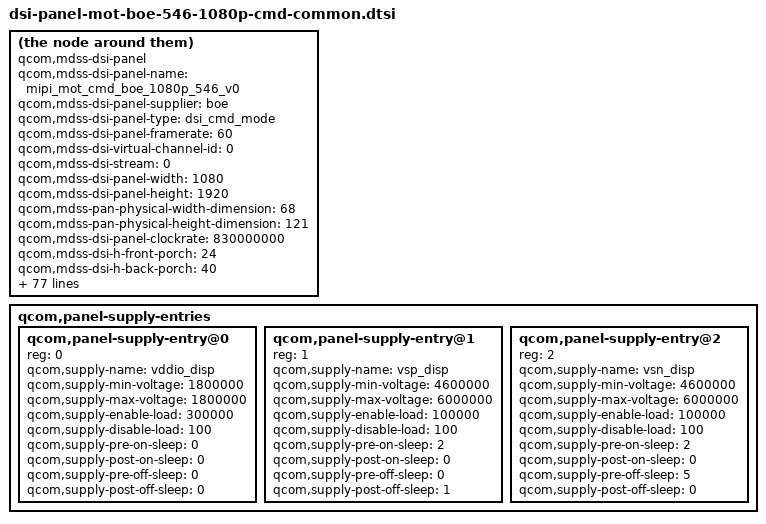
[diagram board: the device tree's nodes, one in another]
/* Copyright (c) 2015, The Linux Foundation. All rights reserved.
 *
 * This program is free software; you can redistribute it and/or modify
 * it under the terms of the GNU General Public License version 2 and
 * only version 2 as published by the Free Software Foundation.
 *
 * This program is distributed in the hope that it will be useful,
 * but WITHOUT ANY WARRANTY; without even the implied warranty of
 * MERCHANTABILITY or FITNESS FOR A PARTICULAR PURPOSE.  See the
 * GNU General Public License for more details.
 */

compatible = "qcom,mdss-dsi-panel";
qcom,mdss-dsi-panel-name = "mipi_mot_cmd_boe_1080p_546_v0";
qcom,mdss-dsi-panel-supplier = "boe";
qcom,mdss-dsi-panel-type = "dsi_cmd_mode";
qcom,mdss-dsi-panel-framerate = <60>;
qcom,mdss-dsi-virtual-channel-id = <0>;
qcom,mdss-dsi-stream = <0>;
qcom,mdss-dsi-panel-width = <1080>;
qcom,mdss-dsi-panel-height = <1920>;
/* Todo: update dimension values based on BOE spec. */
qcom,mdss-pan-physical-width-dimension = <68>;
qcom,mdss-pan-physical-height-dimension = <121>;

qcom,mdss-dsi-panel-clockrate = <830000000>;
qcom,mdss-dsi-h-front-porch = <24>;
qcom,mdss-dsi-h-back-porch = <40>;
qcom,mdss-dsi-h-pulse-width = <4>;
qcom,mdss-dsi-h-sync-skew = <0>;
qcom,mdss-dsi-v-back-porch = <16>;
qcom,mdss-dsi-v-front-porch = <16>;
qcom,mdss-dsi-v-pulse-width = <2>;
qcom,mdss-dsi-h-left-border = <0>;
qcom,mdss-dsi-h-right-border = <0>;
qcom,mdss-dsi-v-top-border = <0>;
qcom,mdss-dsi-v-bottom-border = <0>;
qcom,mdss-dsi-bpp = <24>;
qcom,mdss-dsi-underflow-color = <0xff>;
qcom,mdss-dsi-border-color = <0>;
qcom,mdss-dsi-on-command = [
	05 01 00 00 78 00 01 11
	/* MCS Protect */
	23 00 00 00 00 00 02 B0 00
	/* CABC RGB full PWM */
	29 00 00 00 00 00 02 FA 20
	/* CABC PWM setting */
	29 00 00 00 00 00 18 CE 5D 40 43 49 55 62 71 82 94 A8 B9 CB DB E9 FE FE
		FF 03 15 04 04 00 00
	/* CABC UI mode setting */
	29 00 00 00 00 00 07 B8 07 8B 19 08 0C 21
	/* CABC Moving Image mode setting */
	29 00 00 00 00 00 07 BA 07 7A 64 18 30 8D
	/* Set Max Brightness */
	15 00 00 00 00 00 02 51 CC
	/* Set Minimum Brightness */
	15 00 00 00 00 00 02 5E 00
	/* BLU control */
	15 00 00 00 00 00 02 53 2C
	/* set defaut CABC to UI mode */
	15 00 00 00 00 00 02 55 01
	05 01 00 00 00 00 01 29];
qcom,mdss-dsi-off-command = [
	05 01 00 00 0a 00 01 28
	05 01 00 00 55 00 01 10];

qcom,mdss-dsi-cabc-ui-command = [15 01 00 00 00 00 02 55 01];
qcom,mdss-dsi-cabc-ui-command-state = "dsi_hs_mode";
qcom,mdss-dsi-cabc-mv-command = [15 01 00 00 00 00 02 55 03];
qcom,mdss-dsi-cabc-mv-command-state = "dsi_hs_mode";
qcom,mdss-dsi-cabc-dis-command = [15 01 00 00 00 00 02 55 00];
qcom,mdss-dsi-cabc-dis-command-state = "dsi_hs_mode";
qcom,mdss-dsi-hbm-on-command = [15 01 00 00 00 00 02 51 FF];
qcom,mdss-dsi-hbm-on-command-state = "dsi_hs_mode";
qcom,mdss-dsi-hbm-off-command = [15 01 00 00 00 00 02 51 CC];
qcom,mdss-dsi-hbm-off-command-state = "dsi_hs_mode";
qcom,mdss-dsi-hbm-type = "lcd-dcs-wled";

qcom,mdss-dsi-use-blank-in-progress-notifier;
qcom,mdss-dsi-on-command-state = "dsi_lp_mode";
qcom,mdss-dsi-off-command-state = "dsi_lp_mode";
qcom,mdss-dsi-h-sync-pulse = <0>;
qcom,mdss-dsi-traffic-mode = "burst_mode";
qcom,mdss-dsi-bllp-eof-power-mode;
qcom,mdss-dsi-bllp-power-mode;
qcom,mdss-dsi-lane-0-state;
qcom,mdss-dsi-lane-1-state;
qcom,mdss-dsi-lane-2-state;
qcom,mdss-dsi-lane-3-state;
qcom,mdss-dsi-panel-timings = [DB 34 22 00 62 66 28 36 2B 03 04 00];
qcom,mdss-dsi-t-clk-post = <0x3>;
qcom,mdss-dsi-t-clk-pre = <0x29>;
qcom,mdss-dsi-bl-min-level = <1>;
qcom,mdss-dsi-bl-max-level = <4095>;
qcom,mdss-dsi-bl-on-defer-delay = <60>;
qcom,mdss-dsi-dma-trigger = "trigger_sw";
qcom,mdss-dsi-mdp-trigger = "none";
qcom,mdss-dsi-bl-pmic-control-type = "bl_ctrl_wled";
qcom,mdss-dsi-reset-sequence = <0 11>, <1 21>;
qcom,mdss-dsi-lp11-init;
qcom,mdss-dsi-tx-eot-append;

qcom,mdss-dsi-te-pin-select = <1>;
qcom,mdss-dsi-te-dcs-command = <1>;
qcom,mdss-dsi-te-check-enable;
qcom,mdss-dsi-te-using-te-pin;

qcom,esd-check-enabled;
qcom,mdss-dsi-panel-status-check-mode = "reg_read";
qcom,mdss-dsi-panel-status-command = [06 01 00 01 00 00 01 0A];
qcom,mdss-dsi-panel-status-command-state = "dsi_hs_mode";
qcom,mdss-dsi-panel-status-value = <0x1c>;
qcom,mdss-dsi-panel-on-check-value = <0x1c>;
qcom,partial-update-enabled;
qcom,panel-roi-alignment = <16 2 16 2 320 0>;

qcom,panel-supply-entries {
	#address-cells = <1>;
	#size-cells = <0>;

	qcom,panel-supply-entry@0 {
		reg = <0>;
		qcom,supply-name = "vddio_disp";
		qcom,supply-min-voltage = <1800000>;
		qcom,supply-max-voltage = <1800000>;
		qcom,supply-enable-load = <300000>;
		qcom,supply-disable-load = <100>;
		/* This is always on, no delays needed */
		qcom,supply-pre-on-sleep = <0>;
		qcom,supply-post-on-sleep = <0>;
		qcom,supply-pre-off-sleep = <0>;
		qcom,supply-post-off-sleep = <0>;
	};

	qcom,panel-supply-entry@1 {
		reg = <1>;
		qcom,supply-name = "vsp_disp";
		qcom,supply-min-voltage = <4600000>;
		qcom,supply-max-voltage = <6000000>;
		qcom,supply-enable-load = <100000>;
		qcom,supply-disable-load = <100>;
		qcom,supply-pre-on-sleep = <2>;
		qcom,supply-post-on-sleep = <0>;
		qcom,supply-pre-off-sleep = <0>;
		qcom,supply-post-off-sleep = <1>;
	};

	qcom,panel-supply-entry@2 {
		reg = <2>;
		qcom,supply-name = "vsn_disp";
		qcom,supply-min-voltage = <4600000>;
		qcom,supply-max-voltage = <6000000>;
		qcom,supply-enable-load = <100000>;
		qcom,supply-disable-load = <100>;
		qcom,supply-pre-on-sleep = <2>;
		qcom,supply-post-on-sleep = <0>;
		qcom,supply-pre-off-sleep = <5>;
		qcom,supply-post-off-sleep = <0>;
	};
};
